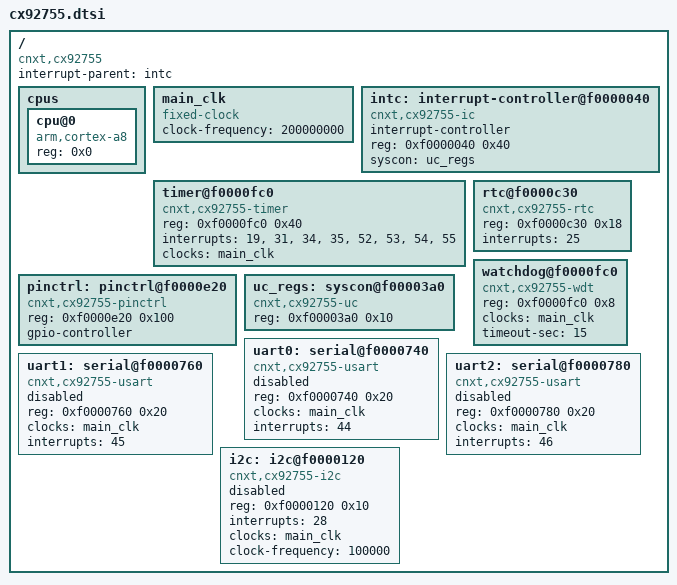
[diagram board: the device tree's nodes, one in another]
/ {
	#address-cells = <1>;
	#size-cells = <1>;
	compatible = "cnxt,cx92755";
	interrupt-parent = <&intc>;
	cpus {
		#address-cells = <1>;
		#size-cells = <0>;
		cpu@0 {
			device_type = "cpu";
			compatible = "arm,cortex-a8";
			reg = <0x0>;
		};
	};
	main_clk: main_clk {
		compatible = "fixed-clock";
		#clock-cells = <0>;
		clock-frequency  = <200000000>;
	};
	intc: interrupt-controller@f0000040 {
		compatible = "cnxt,cx92755-ic";
		interrupt-controller;
		#interrupt-cells = <1>;
		reg = <0xf0000040 0x40>;
		syscon = <&uc_regs>;
	};
	timer@f0000fc0 {
		compatible = "cnxt,cx92755-timer";
		reg = <0xf0000fc0 0x40>;
		interrupts = <19>, <31>, <34>, <35>, <52>, <53>, <54>, <55>;
		clocks = <&main_clk>;
	};
	rtc@f0000c30 {
		compatible = "cnxt,cx92755-rtc";
		reg = <0xf0000c30 0x18>;
		interrupts = <25>;
	};
	watchdog@f0000fc0 {
		compatible = "cnxt,cx92755-wdt";
		reg = <0xf0000fc0 0x8>;
		clocks = <&main_clk>;
		timeout-sec = <15>;
	};
	pinctrl: pinctrl@f0000e20 {
		compatible = "cnxt,cx92755-pinctrl";
		reg = <0xf0000e20 0x100>;
		gpio-controller;
		#gpio-cells = <2>;
	};
	uc_regs: syscon@f00003a0 {
		compatible = "cnxt,cx92755-uc", "syscon";
		reg = <0xf00003a0 0x10>;
	};
	uart0: serial@f0000740 {
		compatible = "cnxt,cx92755-usart";
		reg = <0xf0000740 0x20>;
		clocks = <&main_clk>;
		interrupts = <44>;
		status = "disabled";
	};
	uart1: serial@f0000760 {
		compatible = "cnxt,cx92755-usart";
		reg = <0xf0000760 0x20>;
		clocks = <&main_clk>;
		interrupts = <45>;
		status = "disabled";
	};
	uart2: serial@f0000780 {
		compatible = "cnxt,cx92755-usart";
		reg = <0xf0000780 0x20>;
		clocks = <&main_clk>;
		interrupts = <46>;
		status = "disabled";
	};
	i2c: i2c@f0000120 {
		compatible = "cnxt,cx92755-i2c";
		reg = <0xf0000120 0x10>;
		interrupts = <28>;
		clocks = <&main_clk>;
		clock-frequency = <100000>;
		#address-cells = <1>;
		#size-cells = <0>;
		status = "disabled";
	};
};
